# H3 register map
Vendor: Allwinner; Series: H3; File version: 0.1
CPU: 0, little endian, MPU, no FPU, 0 interrupt priority bits
Registers are 32-bit, read-write, reset 0x0 unless marked. A register's access mark holds for its fields unless they carry their own. Offsets are from the block's base; [hi:lo] are bit positions; {n}, {i} and the like mark numbered series.

## CPUCFG
Base 0x01F01C00
0x00 CPUS_RST_CTRL_REG — CPUS reset control register
  [0] CPUS_RESET — CPUS Reset Assert. 0: assert 1: de-assert.
    0=assert; 1=deassert
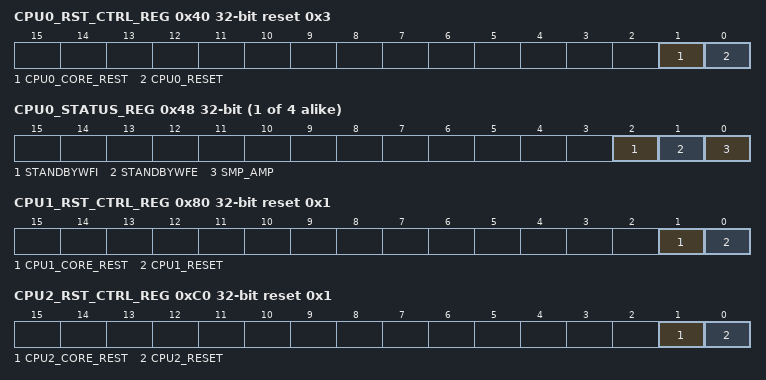
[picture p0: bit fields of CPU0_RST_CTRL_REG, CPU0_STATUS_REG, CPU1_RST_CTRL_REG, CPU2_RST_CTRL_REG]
0x40 CPU0_RST_CTRL_REG reset 0x3
  [1] CPU0_CORE_REST — These are the primary reset signals which initialize the processor logic in the processor power domains, not including the debug, breakpoint and watchpoint logic. 0: assert 1: de-assert.
    0=assert; 1=deassert
  [0] CPU0_RESET — CPU0 Power-on Reset Assert. These power-on reset signals initialize all the processor logic, including CPU Debug, and breakpoint and watch point logic in the processor power domains. They do not reset debug logic in the debug power domain. 0: assert 1: de-assert.
    0=assert; 1=deassert
{0x44+0x40*i} CPU{i}_CTRL_REG (i=0..3) — CPU{i} control register
  [0] CPU{i}_CP15_WRITE_DISABLE — Disable write access to certain CP15 registers. 0: enable 1: disable
    0=enable; 1=disable
{0x48+0x40*i} CPU{i}_STATUS_REG (i=0..3) — CPU{i} status register
  [2] STANDBYWFI ro — Indicates if the processor is in WFI standby mode: 0: Processor not in WFI standby mode. 1: Processor in WFI standby mode
    0=Processor not in WFI standby mode; 1=Processor in WFI standby mode
  [1] STANDBYWFE ro — Indicates if the processor is in the WFE standby mode: 0: Processor not in WFE standby mode 1: Processor in WFE standby mode
    0=Processor not in WFE standby mode; 1=Processor in WFE standby mode
  [0] SMP_AMP ro — 0: AMP mode 1: SMP mode
    0=AMP_mode; 1=SMP_mode
0x80 CPU1_RST_CTRL_REG reset 0x1
  [1] CPU1_CORE_REST — These are the primary reset signals which initialize the processor logic in the processor power domains, not including the debug, breakpoint and watchpoint logic. 0: assert 1: de-assert.
    0=assert; 1=deassert
  [0] CPU1_RESET — CPU1 Power-on Reset Assert. These power-on reset signals initialize all the processor logic, including CPU Debug, and breakpoint and watch point logic in the processor power domains. They do not reset debug logic in the debug power domain. 0: assert 1: de-assert.
    0=assert; 1=deassert
0xC0 CPU2_RST_CTRL_REG reset 0x1
  [1] CPU2_CORE_REST — These are the primary reset signals which initialize the processor logic in the processor power domains, not including the debug, breakpoint and watch point logic. 0: assert 1: de-assert.
    0=assert; 1=deassert
  [0] CPU2_RESET — CPU2 Reset Assert. These power-on reset signals initialize all the processor logic, including CPU Debug, and breakpoint and watch point logic in the processor power domains. They do not reset debug logic in the debug power domain. 0: assert 1: de-assert.
    0=assert; 1=deassert
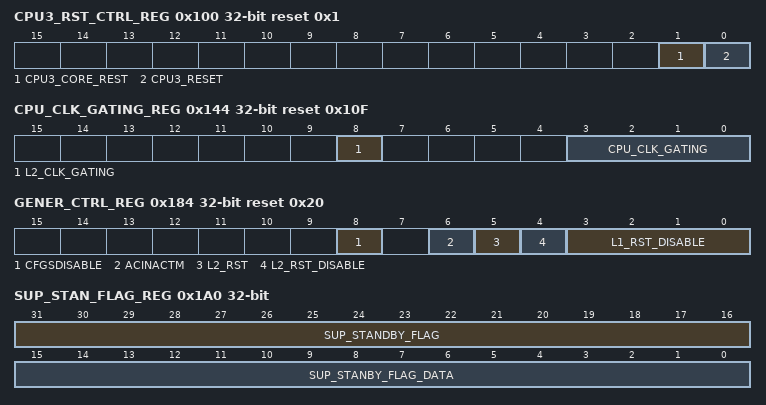
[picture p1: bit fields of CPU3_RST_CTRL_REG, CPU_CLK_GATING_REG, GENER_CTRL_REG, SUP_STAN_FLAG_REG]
0x100 CPU3_RST_CTRL_REG reset 0x1
  [1] CPU3_CORE_REST — These are the primary reset signals which initialize the processor logic in the processor power domains, not including the debug, breakpoint and watch point logic. 0: assert 1: de-assert.
    0=assert; 1=deassert
  [0] CPU3_RESET — CPU3 Reset Assert. These power-on reset signals initialize all the processor logic, including CPU Debug, and breakpoint and watch point logic in the processor power domains. They do not reset debug logic in the debug power domain. 0: assert 1: de-assert.
    0=assert; 1=deassert
0x140 CPU_SYS_RST_REG reset 0x1 — CPU System Reset Register
  [0] CPU — System Reset Control. 0: assert 1: de-assert.
    0=assert; 1=deassert
0x144 CPU_CLK_GATING_REG reset 0x10F — CPU clock gating Register
  [8] L2_CLK_GATING — L2 Clock gating 0: clock off 1: clock on
    0=clock_off; 1=clock_on
  [3:0] CPU_CLK_GATING — CPU0/1/2/3 Clock gating 0: clock off 1: clock on
0x184 GENER_CTRL_REG reset 0x20 — General Control Register
  [8] CFGSDISABLE — Disables write access to some secure GIC registers.
  [6] ACINACTM — Snoop interface is inactive and no longer accepting requests.
  [5] L2_RST — L2 Reset.(SCU global reset) 0: Apply reset to shared L2 memory system controller. 1: Do not apply reset to shared L2 memory system controller.
    0=Apply reset to shared L2 memory system controller; 1=Do not apply reset to shared L2 memory system controller
  [4] L2_RST_DISABLE — Disable automatic L2 cache invalidate at reset: 0: L2 cache is reset by hardware. 1: L2 cache is not reset by hardware.
    0=reset (L2 cache is reset by hardware.); 1=not_reset (L2 cache is not reset by hardware.)
  [3:0] L1_RST_DISABLE — L1 Reset Disable[3:0]. 0: L1 cache is reset by hardware. 1: L1 cache is not reset by hardware.
0x1A0 SUP_STAN_FLAG_REG — Super Standby Flag Register
  [31:16] SUP_STANDBY_FLAG — Key Field. Any value can be written and read back in the key field, but if the values are not appropriate, the lower 16 bits will not change in this register. Only fellow the appropriate process, the super standby flag can be written in the lower 16 bits. Refer to Description and Diagram.
  [15:0] SUP_STANBY_FLAG_DATA — Refer to Description and Diagram
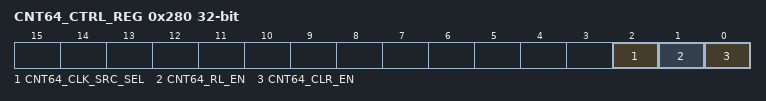
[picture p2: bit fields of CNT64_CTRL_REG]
0x280 CNT64_CTRL_REG — 64-bit Counter Control Register
  [2] CNT64_CLK_SRC_SEL — 64-bit Counter Clock Source Select. 0: OSC24M 1: /
    0=OSC24M
  [1] CNT64_RL_EN — 64-bit Counter Read Latch Enable. 0: no effect, 1: to latch the 64-bit Counter to the Low/Hi registers and it will change to zero after the registers are latched.
    0=no effect, 1: to latch the 64-bit Counter to the Low/Hi registers and it will change to zero after the registers are latched
  [0] CNT64_CLR_EN — 64-bit Counter Clear Enable. 0: no effect, 1: to clear the 64-bit Counter Low/Hi registers and it will change to zero after the registers are cleared. Note: It is not recommended to clear this counter arbitrarily.
    0=no effect, 1: to clear the 64-bit Counter Low/Hi registers and it will change to zero after the registers are cleared. Note: It is not recommended to clear this counter arbitrarily.
0x284 CNT64_LOW_REG — 64-bit Counter Low Register
  [31:0] CNT64_LO — 64-bit Counter [31:0].
0x288 CNT64_High_REG
  [31:0] CNT64_LO — 64-bit Counter [63:32].
